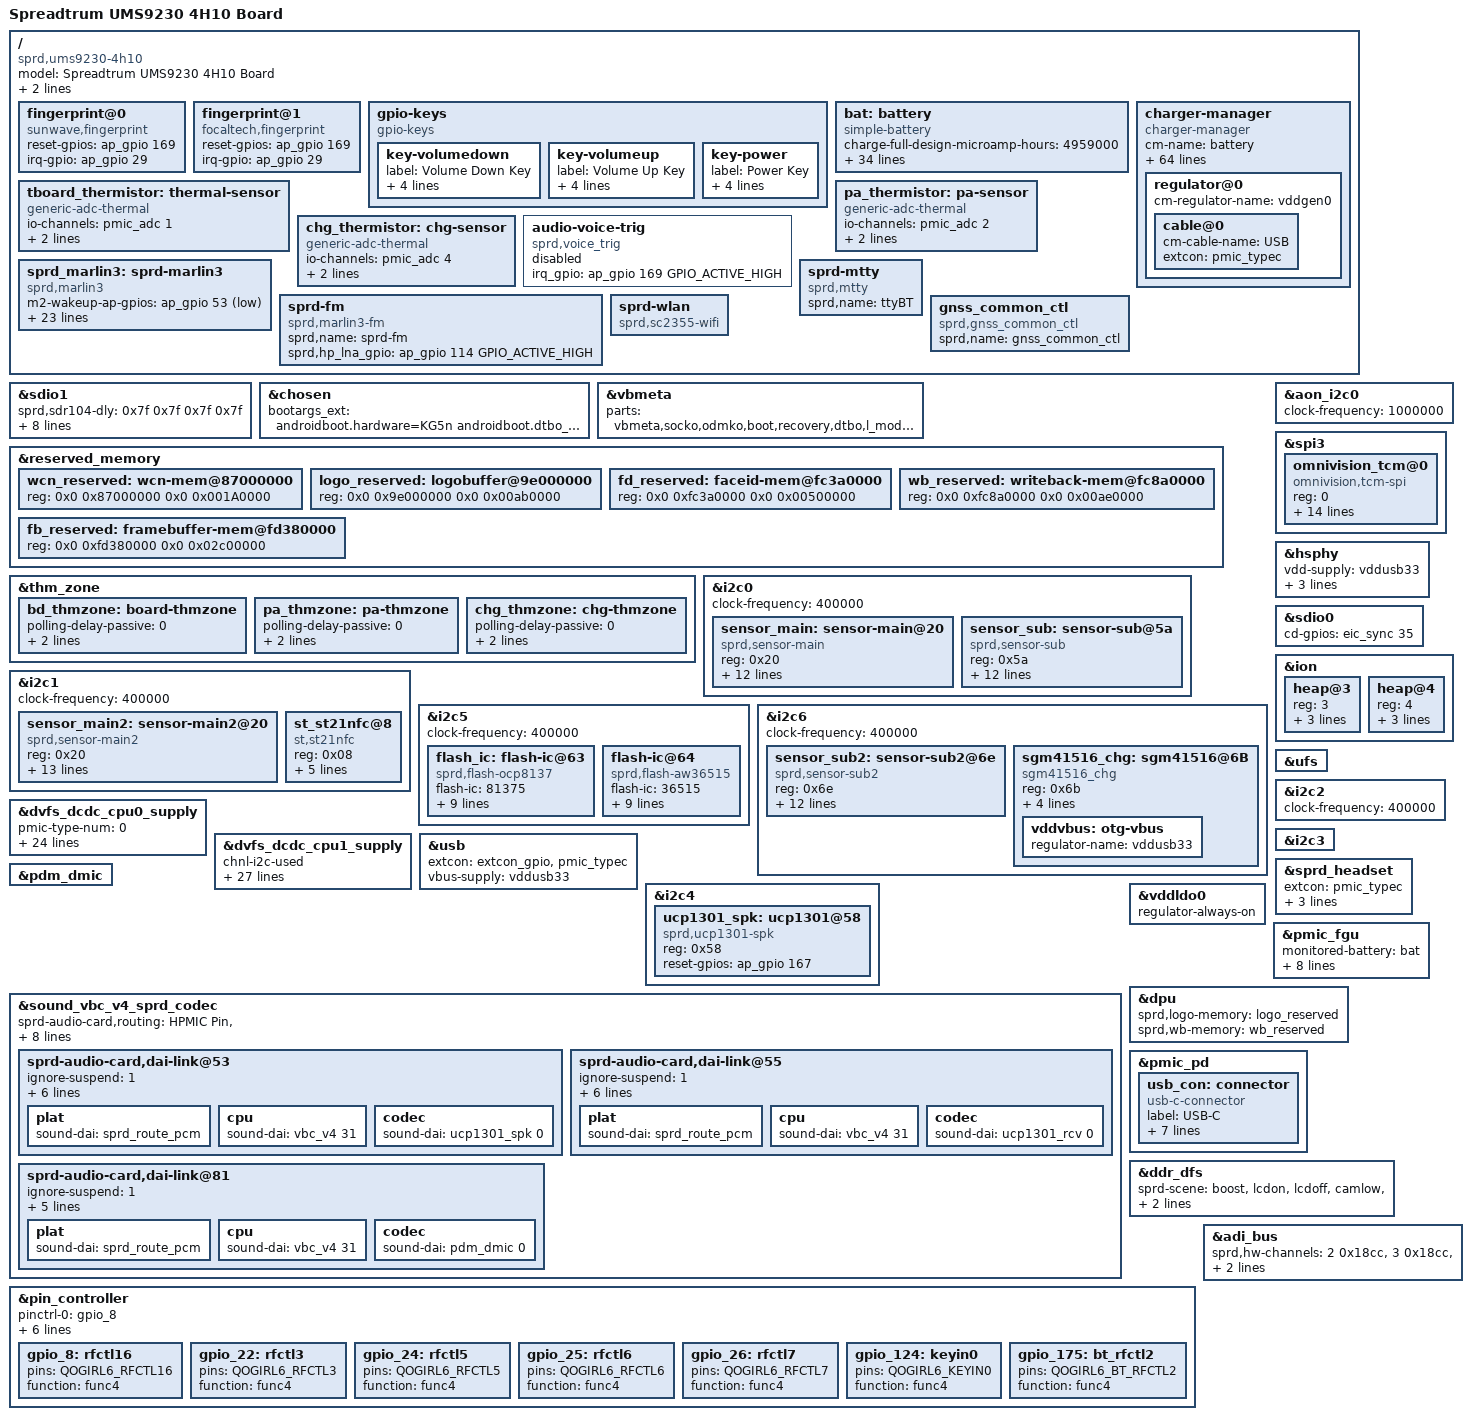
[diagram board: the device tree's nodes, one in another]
/dts-v1/;
/plugin/;
#include <dt-bindings/input/input.h>
#include <dt-bindings/gpio/gpio.h>
#include <dt-bindings/clock/sprd,ums9230-clk.h>
#include <dt-bindings/mfd/sprd,sc2730-regs.h>
#include <dt-bindings/mfd/sprd,sc2730-mask.h>
#include <dt-bindings/usb/pd.h>
// #include "lcd/lcd_dummy_mipi.dtsi"
#include "lcd/lcd_td4160_mipi_hd.dtsi"

/ {

	model = "Spreadtrum UMS9230 4H10 Board";

	compatible = "sprd,ums9230-4h10";

	sprd,sc-id = "ums9230 KG5n 1000";
	sprd,board_id = <0x4100>; //XX00:base board,XX00~XXFF:customize board

	fragment {
		target-path = "/";
		__overlay__ {
			fingerprint@0 {
				compatible = "sunwave,fingerprint";
				reset-gpios = <&ap_gpio 169 GPIO_ACTIVE_HIGH>;
				irq-gpio = <&ap_gpio 29 GPIO_ACTIVE_HIGH>;
			};

			fingerprint@1 {
				compatible = "focaltech,fingerprint";
				reset-gpios = <&ap_gpio 169 GPIO_ACTIVE_HIGH>;
				irq-gpio = <&ap_gpio 29 GPIO_ACTIVE_HIGH>;
			};

			gpio-keys {
				compatible = "gpio-keys";

				key-volumedown {
					label = "Volume Down Key";
					linux,code = <KEY_VOLUMEDOWN>;
					gpios = <&ap_gpio 124 GPIO_ACTIVE_LOW>;
					debounce-interval = <2>;
					wakeup-source;
				};

				key-volumeup {
					label = "Volume Up Key";
					linux,code = <KEY_VOLUMEUP>;
					gpios = <&pmic_eic 4 GPIO_ACTIVE_HIGH>;
					debounce-interval = <2>;
					wakeup-source;
				};

				key-power {
					label = "Power Key";
					linux,code = <KEY_POWER>;
					gpios = <&pmic_eic 1 GPIO_ACTIVE_LOW>;
					debounce-interval = <2>;
					wakeup-source;
				};
			};

			bat: battery {
				compatible = "simple-battery";
				charge-full-design-microamp-hours = <4959000>;
				charge-term-current-microamp = <200000>;
				constant_charge_voltage_max_microvolt = <4400000>;
				factory-internal-resistance-micro-ohms = <125000>;
				voltage-min-design-microvolt = <3450000>;
				charge-pumps-threshold-microvolt = <4100000>;
				ocv-capacity-celsius = <20>;
				ocv-capacity-table-0 = <4313000 100>, <4254000 95>, <4201000 90>,
							<4151000 85>, <4102000 80>, <4060000 75>,
							<4006000 70>, <3973000 65>, <3930000 60>,
							<3882000 55>, <3851000 50>, <3829000 45>,
							<3810000 40>, <3795000 35>, <3781000 30>,
							<3765000 25>, <3746000 20>, <3722000 15>,
							<3694000 10>, <3682000 5>, <3400000 0>;
				voltage-temp-table = <1084000 800>, <975000 850>, <868000 900>,
							  <765000 950>, <668000 1000>, <580000 1050>,
							  <501000 1100>, <430000 1150>, <369000 1200>,
							  <315000 1250>, <270000 1300>, <231000 1350>,
							  <197000 1400>, <169000 1450>, <145000 1500>,
							  <125000 1550>, <108000 1600>, <93000 1650>;
				capacity-temp-table = <45 100>, <25 100>, <10 100>, <0 95>, <(-10) 90>;
				resistance-temp-table = <45 53>, <25 100>, <10 395>, <0 567>, <(-10) 793>;
				charge-sdp-current-microamp = <500000 500000>;
				charge-dcp-current-microamp = <2000000 3000000>;
				charge-cdp-current-microamp = <1500000 1500000>;
				charge-unknown-current-microamp = <500000 500000>;
				charge-fchg-current-microamp = <3250000 3000000>;
				charge-flash-current-microamp = <5000000 2700000>;
				charge-wl-bpp-current-microamp = <1000000 1000000>;
				charge-wl-epp-current-microamp = <2000000 1000000>;
			};

			charger-manager {
				compatible = "charger-manager";
				cm-name = "battery";
				cm-poll-mode = <2>;
				cm-poll-interval = <15000>;
				cm-battery-stat = <2>;

				cm-fullbatt-vchkdrop-ms = <30000>;
				cm-fullbatt-vchkdrop-volt = <60000>;
				cm-fullbatt-voltage = <4350000>;
				cm-fullbatt-current = <200000>;
				cm-fullbatt-capacity = <100>;
				cm-fullbatt-recharging-soc = <60>;
				/*Charge pump target charge current*/
				cm-cp-taper-current = <1000000>;

				cm-chargers = "sgm41516_charger";
				cm-fuel-gauge = "sc27xx-fgu";

				/* in deci centigrade */
				cm-battery-cold = <200>;
				cm-battery-cold-in-minus;
				cm-battery-hot = <600>;
				cm-battery-temp-diff = <50>;

				/* Allow charging for 6hr */
				cm-charging-max = <21600000>;
				/* recovery charging after stop charging 45min */
				cm-discharging-max = <2700000>;

				/* the interval to feed charger watchdog */
				cm-wdt-interval = <60>;

				/* drop voltage in microVolts to allow shutdown */
				cm-shutdown-voltage = <3100000>;

				/* when 99% of the time is exceeded, it will be forced to 100% */
				cm-tickle-time-out = <1500>;

				/* how much time to allow capacity change */
				cm-one-cap-time = <30>;
				/* cm-thermal-zone = "board-thmzone"; */
				/* when the safe charging voltage is exceeded, stop charging */
				cm-charge-voltage-max = <6500000>;
				cm-flash-charge-voltage-max = <11000000>;
				/* drop voltage in microVolts to restart charging */
				cm-charge-voltage-drop = <700000>;

				cm-dcp-jeita-temp-table = <1000 1030 0 4340000>, <1150 1180 700000 4340000>,
					<1450 1420 2000000 4340000>, <1600 1570 700000 4100000>;
				cm-sdp-jeita-temp-table = <1000 1030 0 4340000>, <1150 1180 500000 4340000>,
					<1450 1420 500000 4340000>, <1600 1570 500000 4100000>;
				cm-cdp-jeita-temp-table = <1000 1030 0 4340000>, <1150 1180 700000 4340000>,
					<1450 1420 1500000 4340000>, <1600 1570 700000 4100000>;
				cm-unknown-jeita-temp-table = <1000 1030 0 4340000>, <1150 1180 500000 4340000>,
					<1450 1420 500000 4340000>, <1600 1570 500000 4100000>;
				cm-fchg-jeita-temp-table = <1000 1030 0 4340000>, <1150 1180 700000 4340000>,
					<1450 1420 3250000 4340000>, <1600 1570 700000 4100000>;
				cm-flash-jeita-temp-table = <1000 1030 0 4340000>, <1150 1180 1000000 4340000>,
					<1450 1420 5000000 4340000>, <1600 1570 1000000 4100000>;
				cm-wl-bpp-jeita-temp-table = <1000 1030 0 4340000>, <1150 1180 500000 4340000>,
					<1450 1420 1000000 4340000>, <1600 1570 5000000 4100000>;
				cm-wl-epp-jeita-temp-table = <1000 1030 0 4340000>, <1150 1180 500000 4340000>,
					<1450 1420 2000000 4340000>, <1600 1570 500000 4100000>;

				cm-cap-remap-table = <1 2 3>, <2 3 2>, <98 99 2>, <99 100 3>;

				monitored-battery = <&bat>;

				regulator@0 {
					cm-regulator-name = "vddgen0";
					cable@0 {
						cm-cable-name = "USB";
						extcon = <&pmic_typec>;
					};
				};
			};

			tboard_thermistor: thermal-sensor {
				compatible = "generic-adc-thermal";
				#thermal-sensor-cells = <0>;
				io-channels = <&pmic_adc 1>;
				io-channel-names = "sensor-channel";
				temperature-lookup-table = <
					(-39742) 1131
					(-29777) 1110
					(-19480) 1074
					(-4679) 983
					10110 838
					24805 654
					44922 413
					54903 316
					64895 238
					74884 178
					84883 133
					94883 100
					104880 75
					114889 57
					124872 43 >;
			};

			pa_thermistor: pa-sensor {
				compatible = "generic-adc-thermal";
				#thermal-sensor-cells = <0>;
				io-channels = <&pmic_adc 2>;
				io-channel-names = "sensor-channel";
				temperature-lookup-table = <
					(-39742) 1131
					(-29777) 1110
					(-19480) 1074
					(-4679) 983
					10110 838
					24805 654
					44922 413
					54903 316
					64895 238
					74884 178
					84883 133
					94883 100
					104880 75
					114889 57
					124872 43 >;
			};

			chg_thermistor: chg-sensor {
				compatible = "generic-adc-thermal";
				#thermal-sensor-cells = <0>;
				io-channels = <&pmic_adc 4>;
				io-channel-names = "sensor-channel";
				temperature-lookup-table = <
					(-39742) 1131
					(-29777) 1110
					(-19480) 1074
					(-4679) 983
					10110 838
					24805 654
					44922 413
					54903 316
					64895 238
					74884 178
					84883 133
					94883 100
					104880 75
					114889 57
					124872 43 >;
			};

			audio-voice-trig {
				status = "disable";
				compatible = "sprd,voice_trig";
				irq_gpio = <&ap_gpio 169 GPIO_ACTIVE_HIGH>;
			};

			sprd_marlin3: sprd-marlin3 {
				compatible = "sprd,marlin3";
				m2-wakeup-ap-gpios = <&ap_gpio 53 GPIO_ACTIVE_LOW>;
				reset-gpios = <&ap_gpio 177 GPIO_ACTIVE_LOW>;
				enable-gpios = <&ap_gpio 116 GPIO_ACTIVE_LOW>;
				m2-to-ap-irq-gpios = <&ap_gpio 52 GPIO_ACTIVE_LOW>;
				avdd12-supply = <&vddwcn>;
				avdd33-supply = <&vddwifipa>;
				dcxo18-supply = <&vddsim2>;

				clock-names = "clk_32k","source","enable";
				clocks = <&aon_clk CLK_AUX2>,
					 <&ext_32k>,
					 <&aonapb_gate CLK_AUX2_EB>;

				reg = <0 0x87000000 0 0x00100000>,
					<0 0x87100000 0 0xA0000>;
				reg-names = "btwf_mem", "gnss_mem";

				sdhci-name = <&sdio1>;
				sprd,btwf-file-name = "/dev/block/by-name/wcnmodem";
				sprd,gnss-file-name = "/dev/block/by-name/gnssmodem";
				adma-tx;
				adma-rx;

				/*
				 * bound parameter:
				 * [0]:addr offset, [1]:mask, [2]:unboundval, [3]:boundval
				 */
				avdd12-parent-bound-chip = <REG_ANA_SLP_DCDC_PD_CTRL MASK_ANA_SLP_DCDCGEN1_PD_EN 0x0 MASK_ANA_SLP_DCDCGEN1_PD_EN>;
				avdd12-bound-wbreq = <REG_ANA_LDO_XTL_EN10 MASK_ANA_LDO_VDDWCN_EXT_XTL3_EN 0x0 MASK_ANA_LDO_VDDWCN_EXT_XTL3_EN>;
				avdd33-bound-wbreq = <REG_ANA_LDO_XTL_EN11 MASK_ANA_LDO_VDDWIFIPA_EXT_XTL3_EN 0x0 MASK_ANA_LDO_VDDWIFIPA_EXT_XTL3_EN>;
			};

			sprd-mtty {
				compatible = "sprd,mtty";
				sprd,name = "ttyBT";
			};

			sprd-fm {
				compatible = "sprd,marlin3-fm";
				sprd,name = "sprd-fm";
				sprd,hp_lna_gpio = <&ap_gpio 114 GPIO_ACTIVE_HIGH>;
			};

			gnss_common_ctl {
				compatible = "sprd,gnss_common_ctl";
				sprd,name = "gnss_common_ctl";
			};

			sprd-wlan{
				compatible = "sprd,sc2355-wifi";
			};
		};
	};
};

&sdio1 {
	sprd,sdr104-dly = <0x7f 0x7f 0x7f 0x7f>;
	sprd,sdr50-dly = <0x7f 0x7f 0x8f 0x8f>;
	sd-uhs-sdr104;
	sd-uhs-sdr50;
	bus-width = <4>;
	sprd,name = "sdio_wifi";
	sprd,sdio-adma;
	no-sd;
	no-mmc;
	status = "okay";
};

&chosen {
	bootargs_ext = "androidboot.hardware=KG5n androidboot.dtbo_idx=0";
};

&vbmeta {
	parts = "vbmeta,socko,odmko,boot,recovery,dtbo,l_modem,pm_sys,l_ldsp,l_gdsp,l_agdsp";
};

&reserved_memory {
	wcn_reserved: wcn-mem@87000000 {
		reg = <0x0 0x87000000 0x0 0x001A0000>;
	};

	logo_reserved: logobuffer@9e000000{
		reg = <0x0 0x9e000000 0x0 0x00ab0000>;
	};

	fd_reserved: faceid-mem@fc3a0000 {
		reg = <0x0 0xfc3a0000 0x0 0x00500000>;
	};

	wb_reserved: writeback-mem@fc8a0000 {
		reg = <0x0 0xfc8a0000 0x0 0x00ae0000>;
	};

	fb_reserved: framebuffer-mem@fd380000 {
		reg = <0x0 0xfd380000 0x0 0x02c00000>;
	};
};

&thm_zone {
	bd_thmzone: board-thmzone {
		polling-delay-passive = <0>;
		polling-delay = <0>;
		thermal-sensors = <&tboard_thermistor>;
	};

	pa_thmzone: pa-thmzone {
		polling-delay-passive = <0>;
		polling-delay = <0>;
		thermal-sensors = <&pa_thermistor>;
	};

	chg_thmzone: chg-thmzone {
		polling-delay-passive = <0>;
		polling-delay = <0>;
		thermal-sensors = <&chg_thermistor>;
	};
};

&i2c0 {
	status = "okay";
	clock-frequency = <400000>;

	sensor_main: sensor-main@20 {
		compatible = "sprd,sensor-main";
		reg = <0x20>;
		clock-names = "clk_src","sensor_eb",
			"clk_96m","clk_76m8",
			"clk_48m","clk_26m";
		clocks = <&mm_clk CLK_SENSOR0>,<&mm_gate CLK_MM_SENSOR0_EB>,
				<&pll1 CLK_TWPLL_96M>,<&pll1 CLK_TWPLL_76M8>,
				<&pll1 CLK_TWPLL_48M>,<&ext_26m>;
		vddio-supply = <&vddcamio>;
		vddcama-supply = <&vddcama0>;
		dvdd-gpios = <&ap_gpio 137 0>;
		vddcammot-supply = <&vddcammot>;
		reset-gpios = <&ap_gpio 45 0>;
		power-down-gpios = <&ap_gpio 47 0>;
		sprd,phyid = <0>;
		csi = <&csi0>;
	};

	sensor_sub: sensor-sub@5a {
		compatible = "sprd,sensor-sub";
		reg = <0x5a>;
		clock-names = "clk_src","sensor_eb",
			"clk_96m","clk_76m8",
			"clk_48m","clk_26m";
		clocks = <&mm_clk CLK_SENSOR0>,<&mm_gate CLK_MM_SENSOR0_EB>,
				<&pll1 CLK_TWPLL_96M>,<&pll1 CLK_TWPLL_76M8>,
				<&pll1 CLK_TWPLL_48M>,<&ext_26m>;
		vddio-supply = <&vddcamio>;
		vddcama-supply = <&vddcama0>;
		dvdd-gpios = <&ap_gpio 137 0>;
		vddcammot-supply = <&vddcammot>;
		reset-gpios = <&ap_gpio 44 0>;
		power-down-gpios = <&ap_gpio 46 0>;
	/*	mipi-switch-en-gpios = <&ap_gpio 55 0>;*/
	/*	mipi-switch-mode-gpios = <&ap_gpio 8 0>;*/
		sprd,phyid = <2>;
		csi = <&csi0>;
	};
};

&i2c1 {
	status = "okay";
	clock-frequency = <400000>;

	sensor_main2: sensor-main2@20 {
		compatible = "sprd,sensor-main2";
		reg = <0x20>;
		clock-names = "clk_src","sensor_eb",
			"clk_96m","clk_76m8",
			"clk_48m","clk_26m";
		clocks = <&mm_clk CLK_SENSOR1>,<&mm_gate CLK_MM_SENSOR1_EB>,
				<&pll1 CLK_TWPLL_96M>,<&pll1 CLK_TWPLL_76M8>,
				<&pll1 CLK_TWPLL_48M>,<&ext_26m>;
		vddio-supply = <&vddcamio>;
		vddcama-supply = <&vddcama1>;
		vddcamd-supply = <&vddcamd0>;
		vddcammot-supply = <&vddcammot>;
		mot-gpios = <&ap_gpio 113 0>;
		reset-gpios = <&ap_gpio 41 0>;
		power-down-gpios = <&ap_gpio 40 0>;
	/*	mipi-switch-en-gpios = <&ap_gpio 55 0>;*/
	/*	mipi-switch-mode-gpios = <&ap_gpio 8 0>;*/
		sprd,phyid = <4>;
		csi = <&csi1>;
	};

};

&i2c1 {
	status = "okay";
	clock-frequency = <400000>;

	st_st21nfc@8 {
		compatible = "st,st21nfc";
		reg = <0x08>;
		clkreq-gpio = <&ap_gpio 130 0>;
		reset-gpio = <&ap_gpio 131 0>;
		irq-gpio = <&ap_gpio 133 0>;
		clock-names = "clk_aux0_src", "clk_aux0_eb", "clk_26m";
		clocks = <0xffffffff 0x2 0xffffffff 0x4 0xffffffff>;
	};

};

&i2c5 {
	status = "okay";
	clock-frequency = <400000>;

	flash_ic: flash-ic@63 {
		compatible = "sprd,flash-ocp8137";
		flash-ic = <81375>;
		reg = <0x63>;
		flash-idx = <4>;
		led1-max-torch = <240>;
		led1-max-flash = <480>;
		led2-max-torch = <980>;
		led2-max-flash = <1900>;
		led1_default_torch = <155>;
		led2_default_torch = <190>;
		flash-front-min-current = <115>;
	};

	flash-ic@64 {
		compatible = "sprd,flash-aw36515";
		flash-ic = <36515>;
		reg = <0x64>;
		flash-idx = <4>;
		led1-max-torch = <240>;
		led1-max-flash = <480>;
		led2-max-torch = <980>;
		led2-max-flash = <1900>;
		led1_default_torch = <155>;
		led2_default_torch = <190>;
		flash-front-min-current = <115>;
	};

};

&i2c6 {
	status = "okay";
	clock-frequency = <400000>;

	sensor_sub2: sensor-sub2@6e {
		compatible = "sprd,sensor-sub2";
		reg = <0x6e>;
		clock-names = "clk_src","sensor_eb",
			"clk_96m","clk_76m8",
			"clk_48m","clk_26m";
		clocks = <&mm_clk CLK_SENSOR2>,<&mm_gate CLK_MM_SENSOR2_EB>,
			<&pll1 CLK_TWPLL_96M>,<&pll1 CLK_TWPLL_76M8>,
			<&pll1 CLK_TWPLL_48M>,<&ext_26m>;
		vddio-supply = <&vddcamio>;
		avdd-gpios = <&ap_gpio 130 0>;
		vddcamd-supply = <&vddcamd1>;
		vddcammot-supply = <&vddcammot>;
		mot-gpios = <&ap_gpio 112 0>;
		reset-gpios = <&ap_gpio 114 0>;
	/*	power-down-gpios = <&ap_gpio 40 0>;*/
		sprd,phyid = <3>;
		csi = <&csi2>;
	};

	sgm41516_chg: sgm41516@6B {
		compatible = "sgm41516_chg", "sgm,sgm41516";
		reg = <0x6b>;
		phys = <&hsphy>;
		monitored-battery = <&bat>;
		extcon = <&extcon_gpio>, <&pmic_pd>;
		pd-extcon-enable;
		vddvbus:otg-vbus {
			// regulator-name = "vddvbus";
			regulator-name = "vddusb33";
		};
	};

};

&aon_i2c0 {
	status = "okay";
	clock-frequency = <1000000>;
};

&spi3 {
	status = "okay";
	#address-cells = <1>;
	#size-cells = <0>;

	omnivision_tcm@0 {
		compatible = "omnivision,tcm-spi";
		reg = <0>;
		spi-max-frequency = <9600000>;
		/* TD4160 */
		panel = <&td4160_mipi_hd>;

		omnivision,irq-gpio = <&ap_gpio 144 0x2008>; /* IRQF_ONESHOT | IRQF_TRIGGER_LOW */
		omnivision,irq-on-state = <0>;
		omnivision,reset-gpio = <&ap_gpio 146 GPIO_ACTIVE_HIGH>;
		omnivision,reset-on-state = <0>;
		omnivision,reset-active-ms = <20>;
		omnivision,reset-delay-ms = <200>;
		omnivision,power-delay-ms = <200>;
		omnivision,spi-mode = <3>;
		omnivision,byte-delay-us = <0>;
		omnivision,block-delay-us = <0>;
		omnivision,ubl-max-freq = <3000000>;
		omnivision,ubl-byte-delay-us = <20>;
		// omnivision,display-reset-gpio = <&msm_gpio 78 0>;
		// interrupt-parent = <&ap_gpio>;
		// interrupts = <144 0x2008>;
		// vdd-supply = <&pm8994_lvs2>;
		// avdd-supply = <&pm8994_l22>;
		// pinctrl-names = "pmx_ts_active", "pmx_ts_suspend";
		// pinctrl-0 = <&ts_active>;
		// pinctrl-1 = <&ts_suspend>;
		// omnivision,bus-reg-name = "vdd";
		// omnivision,pwr-reg-name = "avdd";
	};
};

&dvfs_dcdc_cpu0_supply {
	pmic-type-num = <0>;
	slew-rate = <9375>; /* 9375uV/us */
	top-dvfs-adi-state = <0x70 0 0xf>;
	voltage-grade-num = <8>;
	voltage-grade = <0 0xf0 0xf4 0 0x1ff>,
		<1 0xf0 0xf4 9 0x1ff>,
		<2 0x100 0xf4 18 0x1ff>,
		<3 0x110 0xf8 0 0x1ff>,
		<4 0x120 0xf8 9 0x1ff>,
		<5 0x130 0xf8 18 0x1ff>,
		<6 0x140 0xfc 0 0x1ff>,
		<7 0x140 0xfc 9 0x1ff>;
	voltage-up-delay = <50 0x58 0 0xffff 0x600>,
		<100 0x58 16 0xffff 0xa00>,
		<150 0x54 0 0xffff 0xf00>,
		<200 0x54 16 0xffff 0x1400>,
		<250 0x50 0 0xffff 0x1900>,
		<300 0x50 16 0xffff 0x1e00>,
		<350 0x110 0 0xffff 0x2300>;
	voltage-down-delay = <50 0x64 0 0xffff 0x600>,
		<100 0x64 16 0xffff 0xa00>,
		<150 0x60 0 0xffff 0xf00>,
		<200 0x60 16 0xffff 0x1400>,
		<250 0x5c 0 0xffff 0x1900>,
		<300 0x5c 16 0xffff 0x1e00>,
		<350 0x114 0 0xffff 0x2300>;
	tuning-latency-us = <0>;
	chnl-in-i2c = <0>;
};

&dvfs_dcdc_cpu1_supply {
	chnl-i2c-used;
	third-pmic-used;
	pmic-type-num = <2>;
	slew-rate = <4000>; /* 4000uV/us */
	supply-type-sel = <0x120 0 1>;
	top-dvfs-i2c-state = <0x9c 4 0x1f>;
	voltage-grade-num = <8>;
	voltage-grade = <0 0x8f 0x12c 0 0xff>,
		<1 0x94 0x12c 8 0xff>,
		<2 0x99 0x12c 16 0xff>,
		<3 0x9e 0x12c 24 0xff>,
		<4 0xa3 0x130 0 0xff>,
		<5 0xa8 0x130 8 0xff>,
		<6 0xa8 0x130 16 0xff>,
		<7 0xa8 0x130 24 0xff>;
	voltage-up-delay = <50 0x84 0 0xffff 0x1600>,
		<100 0x84 16 0xffff 0x1a00>,
		<150 0x80 0 0xffff 0x1f00>,
		<200 0x80 16 0xffff 0x2400>,
		<250 0x7c 0 0xffff 0x2900>,
		<300 0x7c 16 0xffff 0x2e00>,
		<350 0x118 0 0xffff 0x3300>;
	voltage-down-delay = <50 0x90 0 0xffff 0x600>,
		<100 0x90 16 0xffff 0xa00>,
		<150 0x8c 0 0xffff 0xf00>,
		<200 0x8c 16 0xffff 0x1400>,
		<250 0x88 0 0xffff 0x1900>,
		<300 0x88 16 0xffff 0x1e00>,
		<350 0x11c 0 0xffff 0x2300>;
	tuning-latency-us = <0>;
	chnl-in-i2c = <1>;
};

&hsphy {
	vdd-supply = <&vddusb33>;
	extcon = <&extcon_gpio>;
	sprd,hsphy-device-eye-pattern = <0x04f3d1c0>;
	sprd,hsphy-host-eye-pattern = <0x04f3d1c0>;
	status = "okay";
};

&usb {
	extcon = <&extcon_gpio>, <&pmic_typec>;
	vbus-supply = <&vddusb33>;
	status = "okay";
};

&sdio0 {
	cd-gpios = <&eic_sync 35 GPIO_ACTIVE_HIGH>;
};

&ion {
	heap@3 {
		reg = <3>;
		label = "carveout_fb";
		type = <2>;
		memory-region = <&fb_reserved>;
	};
};

&ufs {
	status = "okay";
};

&i2c2 {
	status = "okay";
	clock-frequency = <400000>;
};

&i2c3 {
	status = "okay";
};

&i2c4 {
	status = "okay";
	ucp1301_spk: ucp1301@58 {
		compatible = "sprd,ucp1301-spk";
		reg = <0x58>;
		reset-gpios = <&ap_gpio 167 GPIO_ACTIVE_HIGH>;
		#sound-dai-cells = <1>;
	};
};

&sprd_headset {
	status = "okay";
	extcon = <&pmic_typec>;
	mic-gpios = <&ap_gpio 175 GPIO_ACTIVE_HIGH>;
	lr-gpios = <&ap_gpio 174 GPIO_ACTIVE_HIGH>;
	sprd,3pole-adc-threshold = <112>;
};

&pdm_dmic {
	status = "okay";
};

&sound_vbc_v4_sprd_codec {
	status = "okay";
	sprd-audio-card,routing =
		"HPMIC Pin", "HP Mic Jack",
		"MIC Pin", "Mic Jack",
		"MIC2 Pin", "Aux Mic Jack",
		"HeadPhone Jack", "HP Pin",
		"Ext Spk", "SPK Pin",
		"UCP1301 SPK ON", "SPK Pin",
		"Ext Spk", "UCP1301 SPK",
		"PDM DMIC2 ON", "SPK Pin",
		"Ext Spk", "PDM_DMIC2",
		"DMIC Pin", "DMic Jack",
		"DMIC1 Pin", "DMic1 Jack",
		"Ext Ear", "EAR Pin",
		"UCP1301 RCV ON", "EAR Pin",
		"Ext Ear", "UCP1301 RCV";

	/* 35: ucp1301 normal ap01 */
	sprd-audio-card,dai-link@53 {
		ignore-suspend = <1>;
		link-name = "BE_NORMAL_AP01_UCPSPK";
		stream-name = "BE_ST_NORMAL_AP01_UCPSPK";
		no-pcm = <1>;
		dpcm-playback = <1>;
		be-id = <0>;
		dai-format = "i2s";
		plat {
			sound-dai = <&sprd_route_pcm>;
		};
		cpu {
			sound-dai = <&vbc_v4 31>;
		};
		codec {
			sound-dai = <&ucp1301_spk 0>;
		};
	};

	/*
	 * node 54 and node 55 (index 36 and 37) are reserved for
	 * "ucp1301-spk2" and "ucp1301-rcv"
	 * nodes from 56 to 67 (index from 38 to 49) are used by HIFI
	 */
	/* 37: ucp1301 normal ap01 rcv */
	sprd-audio-card,dai-link@55 {
		ignore-suspend = <1>;
		link-name = "BE_NORMAL_AP01_UCPRCV";
		stream-name = "BE_ST_NORMAL_AP01_UCPRCV";
		no-pcm = <1>;
		dpcm-playback = <1>;
		be-id = <0>;
		dai-format = "i2s";
		plat {
			sound-dai = <&sprd_route_pcm>;
		};
		cpu {
			sound-dai = <&vbc_v4 31>;
		};
		codec {
			sound-dai = <&ucp1301_rcv 0>;
		};
	};

	/* 63: pdm dmic */
	sprd-audio-card,dai-link@81 {
		ignore-suspend = <1>;
		link-name = "BE_PDM_DMIC";
		stream-name = "BE_ST_PDM_DMIC";
		no-pcm = <1>;
		dpcm-capture = <1>;
		be-id = <0>;
		//dai-format = "i2s";
		plat {
			sound-dai = <&sprd_route_pcm>;
		};
		cpu {
			sound-dai = <&vbc_v4 31>;
		};
		codec {
			sound-dai = <&pdm_dmic 0>;
		};
	};
};

&vddldo0 {
	regulator-always-on;
};

&pmic_fgu {
	monitored-battery = <&bat>;
	sprd,calib-resistance-real = <4850>;
	sprd,calib-resistance-spec = <20000>;
	first-calib-voltage = <3580000>;
	first-calib-capacity = <50>;
	fgu-capacity-track;
	fullbatt-track-end-vol = <4295>;
	fullbatt-track-end-cur = <130>;
	phys = <&hsphy>;
};

&dpu {
	sprd,logo-memory = <&logo_reserved>;
	sprd,wb-memory = <&wb_reserved>;
};

&pmic_pd {
	status = "okay";
	usb_con: connector {
		compatible = "usb-c-connector";
		label = "USB-C";
		power-role = "dual";
		try-power-role = "sink";
		source-pdos = <PDO_FIXED(5000, 400, PDO_FIXED_USB_COMM)>;
		sink-pdos = <PDO_FIXED(5000, 2000, PDO_FIXED_USB_COMM)
			     PDO_PPS_APDO(3300, 11000, 3000)>;
		op-sink-microwatt = <10000000>;
	};
};

&ddr_dfs {
	  sprd-scene = "boost", "lcdon", "lcdoff", "camlow",
			"camhigh", "camveryhigh", "faceid";
	  sprd-freq = <1333 768 256 1333 1333 0xbacd 1333>;
};

&pin_controller {
	pinctrl-names =
	/* rfctl16 ,rfctl3, rfctl5 */
	"gpio_8", "gpio_22", "gpio_24",
	/* rfctl6, rfctl7, keyin0 */
	"gpio_25", "gpio_26", "gpio_124",
	/* bt_rfctl2 */
	"gpio_175";
	pinctrl-0 = <&gpio_8>;
	pinctrl-1 = <&gpio_22>;
	pinctrl-2 = <&gpio_24>;
	pinctrl-3 = <&gpio_25>;
	pinctrl-4 = <&gpio_26>;
	pinctrl-5 = <&gpio_124>;
	pinctrl-6 = <&gpio_175>;

	gpio_8: rfctl16 {
		pins = "QOGIRL6_RFCTL16";
		function = "func4";
	};

	gpio_22: rfctl3 {
		pins = "QOGIRL6_RFCTL3";
		function = "func4";
	};

	gpio_24: rfctl5 {
		pins = "QOGIRL6_RFCTL5";
		function = "func4";
	};

	gpio_25: rfctl6 {
		pins = "QOGIRL6_RFCTL6";
		function = "func4";
	};

	gpio_26: rfctl7 {
		pins = "QOGIRL6_RFCTL7";
		function = "func4";
	};

	gpio_124: keyin0 {
		pins = "QOGIRL6_KEYIN0";
		function = "func4";
	};

	gpio_175: bt_rfctl2 {
		pins = "QOGIRL6_BT_RFCTL2";
		function = "func4";
	};
};

&ion {
	heap@4 {
		reg = <4>;
		label = "carveout_fd";
		type = <2>;
		memory-region = <&fd_reserved>;
	};
};

&adi_bus {
	sprd,hw-channels = <2 0x18cc>, <3 0x18cc>, <13 0x1854>, <15 0x1874>,
			<17 0x1844>,<19 0x1844>, <21 0x1864>, <30 0x1820>,
			<35 0x19b8>, <39 0x19ac>;
};
